VERSION ""

NS_ :

BS_:

BU_: NODE0 NODE1 NODE2 NODE3 NODE4 NODE5 NODE6 NODE7 Message4

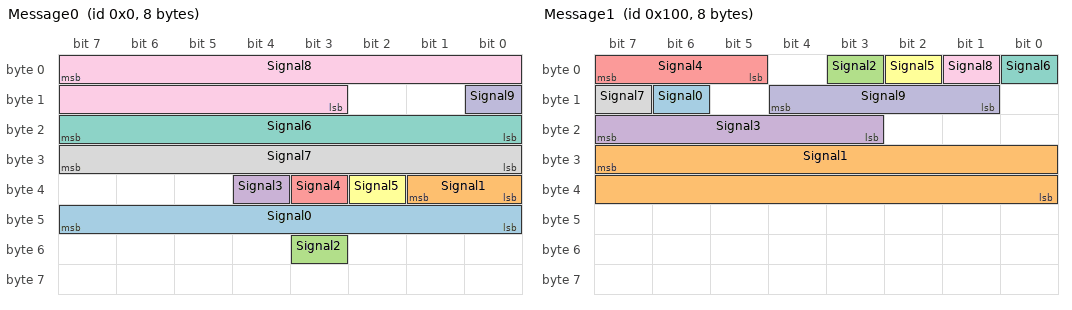
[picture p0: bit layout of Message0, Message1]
BO_ 0 Message0: 8 NODE0
 SG_ Signal0 : 47|8@0+ (1,0) [0|255] "" Vector__XXX
 SG_ Signal1 : 33|2@0+ (1,0) [0|3] "" Vector__XXX
 SG_ Signal2 : 51|1@0+ (1,0) [0|1] "" Vector__XXX
 SG_ Signal3 : 36|1@0+ (1,0) [0|1] "" Vector__XXX
 SG_ Signal4 : 35|1@0+ (1,0) [0|1] "" Vector__XXX
 SG_ Signal5 : 34|1@0+ (1,0) [0|1] "" Vector__XXX
 SG_ Signal6 : 23|8@0+ (1,-40) [-40|215] "U" Vector__XXX
 SG_ Signal7 : 31|8@0+ (0.25,0) [0|99.6] "U" Vector__XXX
 SG_ Signal8 : 7|13@0+ (0.25,0) [0|260] "U" Vector__XXX
 SG_ Signal9 : 8|1@0+ (1,0) [0|1] "" Vector__XXX

BO_ 256 Message1: 8 NODE1
 SG_ Signal0 : 14|1@0+ (1,0) [0|1] "" Vector__XXX
 SG_ Signal1 : 31|16@0+ (0.25,-16) [-16|16] "U" Vector__XXX
 SG_ Signal2 : 3|1@0+ (1,0) [0|1] "" Vector__XXX
 SG_ Signal3 : 23|5@0+ (1,0) [0|31] "" Vector__XXX
 SG_ Signal4 : 7|3@0+ (1,0) [0|7] "" Vector__XXX
 SG_ Signal5 : 2|1@0+ (1,0) [0|1] "" Vector__XXX
 SG_ Signal6 : 0|1@0+ (1,0) [0|1] "" Vector__XXX
 SG_ Signal7 : 15|1@0+ (1,0) [0|1] "" Vector__XXX
 SG_ Signal8 : 1|1@0+ (1,0) [0|1] ""  Message4
 SG_ Signal9 : 12|4@0+ (1,0) [0|15] "" Vector__XXX

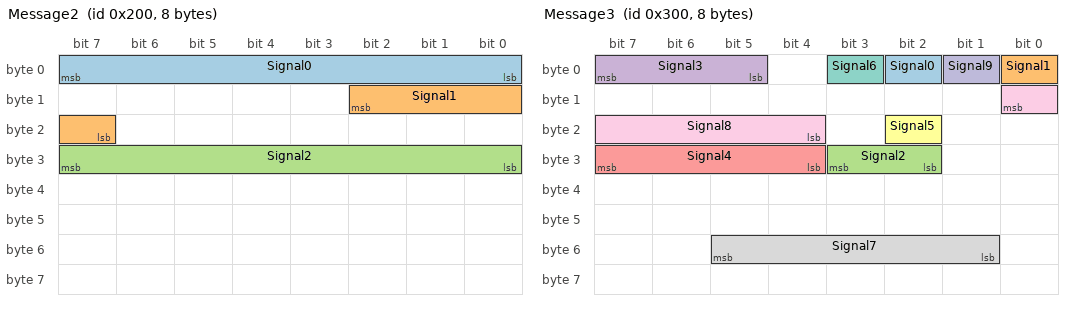
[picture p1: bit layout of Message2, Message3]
BO_ 512 Message2: 8 NODE2
 SG_ Signal0 : 7|8@0+ (1,0) [0|254] "U" Vector__XXX
 SG_ Signal1 : 10|4@0+ (1,0) [0|15] "" Vector__XXX
 SG_ Signal2 : 31|8@0+ (1,0) [0|255] "" Vector__XXX

BO_ 768 Message3: 8 NODE3
 SG_ Signal0 : 2|1@0+ (1,0) [0|1] "" Vector__XXX
 SG_ Signal1 : 0|1@0+ (1,0) [0|1] "" Vector__XXX
 SG_ Signal2 : 27|2@0+ (1,0) [0|3] "" Vector__XXX
 SG_ Signal3 : 7|3@0+ (1,0) [0|7] "" Vector__XXX
 SG_ Signal4 : 31|4@0+ (1,0) [0|15] "" Vector__XXX
 SG_ Signal5 : 18|1@0+ (1,0) [0|1] "" Vector__XXX
 SG_ Signal6 : 3|1@0+ (1,0) [0|1] "" Vector__XXX
 SG_ Signal7 : 53|5@0+ (0.1,0) [0|2.4] "U" Vector__XXX
 SG_ Signal8 : 8|5@0+ (0.1,0) [0|1.5] "bar" Vector__XXX
 SG_ Signal9 : 1|1@0+ (1,0) [0|1] "" Vector__XXX

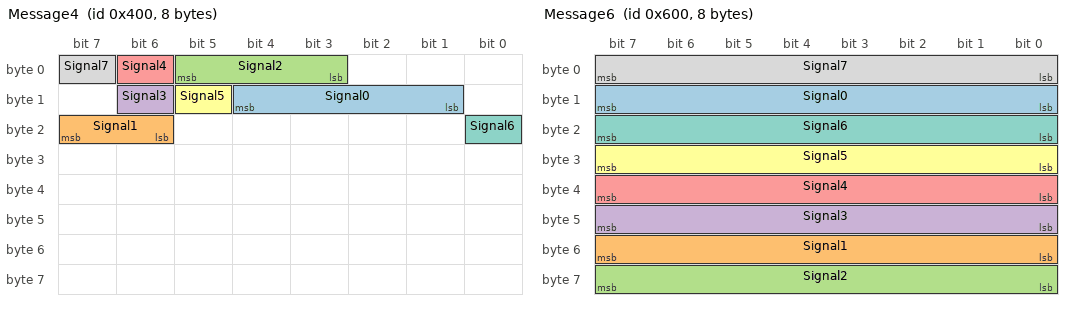
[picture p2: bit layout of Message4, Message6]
BO_ 1024 Message4: 8 NODE4
 SG_ Signal0 : 12|4@0+ (1,0) [0|15] "" Vector__XXX
 SG_ Signal1 : 23|2@0+ (1,0) [0|3] "" Vector__XXX
 SG_ Signal2 : 5|3@0+ (1,0) [0|7] "" Vector__XXX
 SG_ Signal3 : 14|1@0+ (1,0) [0|1] "" Vector__XXX
 SG_ Signal4 : 6|1@0+ (1,0) [0|1] "" Vector__XXX
 SG_ Signal5 : 13|1@0+ (1,0) [0|1] "" Vector__XXX
 SG_ Signal6 : 16|1@0+ (1,0) [0|1] "" Vector__XXX
 SG_ Signal7 : 7|1@0+ (1,0) [0|1] "" Vector__XXX

BO_ 1280 Message5: 8 NODE5
 SG_ Signal0 : 0|8@0+ (1,0) [0|256] "U" Vector__XXX
 SG_ Signal1 : 7|2@0+ (1,0) [0|3] "" Vector__XXX
 SG_ Signal2 : 3|4@0+ (1,0) [0|15] "" Vector__XXX
 SG_ Signal3 : 46|8@0+ (1,0) [0|255] "" Vector__XXX
 SG_ Signal4 : 4|1@0+ (1,0) [0|1] "" Vector__XXX
 SG_ Signal5 : 30|9@0+ (1,0) [0|260] "U" Vector__XXX

BO_ 1536 Message6: 8 NODE6
 SG_ Signal0 : 15|8@0+ (1,0) [0|255] "" Vector__XXX
 SG_ Signal1 : 55|8@0+ (1,0) [0|255] "" Vector__XXX
 SG_ Signal2 : 63|8@0+ (1,0) [0|255] "" Vector__XXX
 SG_ Signal3 : 47|8@0+ (1,0) [0|255] "" Vector__XXX
 SG_ Signal4 : 39|8@0+ (1,0) [0|255] "" Vector__XXX
 SG_ Signal5 : 31|8@0+ (1,0) [0|255] "" Vector__XXX
 SG_ Signal6 : 23|8@0+ (1,0) [0|255] "" Vector__XXX
 SG_ Signal7 : 7|8@0+ (1,0) [0|255] "" Vector__XXX

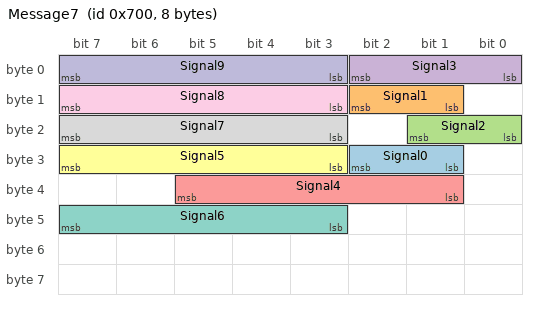
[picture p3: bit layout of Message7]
BO_ 1792 Message7: 8 NODE7
 SG_ Signal0 : 26|2@0+ (1,0) [0|3] "" Vector__XXX
 SG_ Signal1 : 10|2@0+ (1,0) [0|3] "-" Vector__XXX
 SG_ Signal2 : 17|2@0+ (1,0) [0|3] "-" Vector__XXX
 SG_ Signal3 : 2|3@0+ (1,0) [0|7] "-" Vector__XXX
 SG_ Signal4 : 37|5@0+ (1,0) [0|31] "-" Vector__XXX
 SG_ Signal5 : 31|5@0+ (1,0) [0|31] "-" Vector__XXX
 SG_ Signal6 : 47|5@0+ (1,0) [0|31] "-" Vector__XXX
 SG_ Signal7 : 23|5@0+ (1,0) [0|31] "-" Vector__XXX
 SG_ Signal8 : 15|5@0+ (1,0) [0|31] "-" Vector__XXX
 SG_ Signal9 : 7|5@0+ (1,0) [0|31] "-" Vector__XXX

BA_DEF_ SG_  "GenSigStartValue" INT 0 10000;
BA_DEF_ SG_  "GenSigSendType" ENUM  "Cyclic","OnWrite","OnWriteWithRepetition","OnChange","OnChangeWithRepetition","IfActive","IfActiveWithRepetition","NoSigSendType","NotUsed","NotUsed","NotUsed","NotUsed","NotUsed";
BA_DEF_ BO_  "GenMsgILSupport" ENUM  "No","Yes";
BA_DEF_ BO_  "GenMsgCycleTime" INT 0 50000;
BA_DEF_ BO_  "GenMsgSendType" ENUM  "Cyclic","NotUsed","NotUsed","NotUsed","NotUsed","Cyclic","NotUsed","IfActive","NoMsgSendType","NotUsed","vector_leerstring";
BA_DEF_  "BusType" STRING ;
BA_DEF_  "NmBaseAddress" HEX 1024 1087;
BA_DEF_DEF_  "GenSigStartValue" 0;
BA_DEF_DEF_  "GenSigSendType" "Cyclic";
BA_DEF_DEF_  "GenMsgILSupport" "Yes";
BA_DEF_DEF_  "GenMsgCycleTime" 0;
BA_DEF_DEF_  "GenMsgSendType" "NoMsgSendType";
BA_DEF_DEF_  "BusType" "";
BA_DEF_DEF_  "NmBaseAddress" 1024;
BA_ "BusType" "CAN";
BA_ "GenMsgSendType" BO_ 0 0;
BA_ "GenMsgCycleTime" BO_ 0 10;
BA_ "GenMsgCycleTime" BO_ 256 20;
BA_ "GenMsgSendType" BO_ 256 0;
BA_ "GenMsgCycleTime" BO_ 512 256;
BA_ "GenMsgSendType" BO_ 512 0;
BA_ "GenMsgCycleTime" BO_ 768 256;
BA_ "GenMsgSendType" BO_ 768 0;
BA_ "GenMsgCycleTime" BO_ 1024 256;
BA_ "GenMsgSendType" BO_ 1024 0;
BA_ "GenMsgCycleTime" BO_ 1280 20;
BA_ "GenMsgSendType" BO_ 1280 0;
BA_ "GenMsgSendType" BO_ 1536 7;
BA_ "GenMsgSendType" BO_ 1792 0;
BA_ "GenMsgCycleTime" BO_ 1792 50;
BA_ "GenSigStartValue" SG_ 0 Signal6 40;
VAL_ 0 Signal2 1 "State1" 0 "State0" ;
VAL_ 0 Signal3 1 "State1" 0 "State0" ;
VAL_ 0 Signal4 1 "State1" 0 "State0" ;
VAL_ 0 Signal5 1 "State1" 0 "State0" ;
VAL_ 0 Signal9 1 "State1" 0 "State0" ;
VAL_ 256 Signal0 1 "State1" 0 "State0" ;
VAL_ 256 Signal2 1 "State1" 0 "State0" ;
VAL_ 256 Signal3 6 "State6" 5 "State5" 4 "State4" 3 "State3" 2 "State2" 1 "State1" 0 "State0" ;
VAL_ 256 Signal4 7 "State7" 6 "State6" 5 "State5" 4 "State4" 3 "State3" 2 "State2" 1 "State1" 0 "State0" ;
VAL_ 256 Signal5 1 "State1" 0 "State0" ;
VAL_ 256 Signal6 1 "State1" 0 "State0" ;
VAL_ 256 Signal7 1 "State1" 0 "State0" ;
VAL_ 256 Signal8 1 "State1" 0 "State0" ;
VAL_ 768 Signal0 1 "State1" 0 "State0" ;
VAL_ 768 Signal1 1 "State1" 0 "State0" ;
VAL_ 768 Signal2 3 "State3" 2 "State2" 1 "State1" 0 "State0" ;
VAL_ 768 Signal3 7 "State7" 6 "State6" 5 "State5" 4 "State4" 3 "State3" 2 "State2" 1 "State1" 0 "State0" ;
VAL_ 768 Signal4 15 "State15" 14 "State14" 13 "State13" 12 "State12" 11 "State11" 10 "State10" 9 "State9" 8 "State8" 7 "State7" 6 "State6" 5 "State5" 4 "State4" 3 "State3" 2 "State2" 1 "State1" 0 "State0" ;
VAL_ 768 Signal5 1 "State1" 0 "State0" ;
VAL_ 768 Signal6 1 "State1" 0 "State0" ;
VAL_ 768 Signal9 1 "State1" 0 "State0" ;
VAL_ 1024 Signal0 30 "State30" 25 "State25" 24 "State24" 23 "State23" 22 "State22" 21 "State21" 20 "State20" 19 "State19" 18 "State18" 17 "State17" 16 "State16" 15 "State15" 14 "State14" 13 "State13" 12 "State12" 11 "State11" 10 "State10" 9 "State9" 8 "State8" 7 "State7" 6 "State6" 5 "State5" 4 "State4" 3 "State3" 2 "State2" 1 "State1" 0 "State0" ;
VAL_ 1024 Signal1 3 "State3" 2 "State2" 1 "State1" 0 "State0" ;
VAL_ 1024 Signal2 7 "State7" 6 "State6" 5 "State5" 4 "State4" 3 "State3" 2 "State2" 1 "State1" 0 "State0" ;
VAL_ 1024 Signal3 1 "State1" 0 "State0" ;
VAL_ 1024 Signal4 1 "State1" 0 "State0" ;
VAL_ 1024 Signal5 1 "State1" 0 "State0" ;
VAL_ 1024 Signal6 1 "State1" 0 "State0" ;
VAL_ 1024 Signal7 1 "State1" 0 "State0" ;
VAL_ 1280 Signal1 3 "State3" 2 "State2" 1 "State1" 0 "State0" ;
VAL_ 1280 Signal4 1 "State1" 0 "State0" ;
VAL_ 1792 Signal0 3 "State3" 2 "State2" 1 "State1" 0 "State0" ;
VAL_ 1792 Signal1 2 "State2" 1 "State1" 0 "State0" ;
VAL_ 1792 Signal2 2 "State2" 1 "State1" 0 "State0" ;
VAL_ 1792 Signal3 5 "State5" 4 "State4" 3 "State3" 2 "State2" 1 "State1" 0 "State0" ;
VAL_ 1792 Signal4 30 "State30" 25 "State25" 24 "State24" 23 "State23" 22 "State22" 21 "State21" 20 "State20" 19 "State19" 18 "State18" 17 "State17" 16 "State16" 15 "State15" 14 "State14" 13 "State13" 12 "State12" 11 "State11" 10 "State10" 9 "State9" 8 "State8" 7 "State7" 6 "State6" 5 "State5" 4 "State4" 3 "State3" 2 "State2" 1 "State1" 0 "State0" ;
VAL_ 1792 Signal5 30 "State30" 25 "State25" 24 "State24" 23 "State23" 22 "State22" 21 "State21" 20 "State20" 19 "State19" 18 "State18" 17 "State17" 16 "State16" 15 "State15" 14 "State14" 13 "State13" 12 "State12" 11 "State11" 10 "State10" 9 "State9" 8 "State8" 7 "State7" 6 "State6" 5 "State5" 4 "State4" 3 "State3" 2 "State2" 1 "State1" 0 "State0" ;
VAL_ 1792 Signal6 30 "State30" 25 "State25" 24 "State24" 23 "State23" 22 "State22" 21 "State21" 20 "State20" 19 "State19" 18 "State18" 17 "State17" 16 "State16" 15 "State15" 14 "State14" 13 "State13" 12 "State12" 11 "State11" 10 "State10" 9 "State9" 8 "State8" 7 "State7" 6 "State6" 5 "State5" 4 "State4" 3 "State3" 2 "State2" 1 "State1" 0 "State0" ;
VAL_ 1792 Signal7 30 "State30" 25 "State25" 24 "State24" 23 "State23" 22 "State22" 21 "State21" 20 "State20" 19 "State19" 18 "State18" 17 "State17" 16 "State16" 15 "State15" 14 "State14" 13 "State13" 12 "State12" 11 "State11" 10 "State10" 9 "State9" 8 "State8" 7 "State7" 6 "State6" 5 "State5" 4 "State4" 3 "State3" 2 "State2" 1 "State1" 0 "State0" ;
VAL_ 1792 Signal8 30 "State30" 25 "State25" 24 "State24" 23 "State23" 22 "State22" 21 "State21" 20 "State20" 19 "State19" 18 "State18" 17 "State17" 16 "State16" 15 "State15" 14 "State14" 13 "State13" 12 "State12" 11 "State11" 10 "State10" 9 "State9" 8 "State8" 7 "State7" 6 "State6" 5 "State5" 4 "State4" 3 "State3" 2 "State2" 1 "State1" 0 "State0" ;
VAL_ 1792 Signal9 30 "State30" 25 "State25" 24 "State24" 23 "State23" 22 "State22" 21 "State21" 20 "State20" 19 "State19" 18 "State18" 17 "State17" 16 "State16" 15 "State15" 14 "State14" 13 "State13" 12 "State12" 11 "State11" 10 "State10" 9 "State9" 8 "State8" 7 "State7" 6 "State6" 5 "State5" 4 "State4" 3 "State3" 2 "State2" 1 "State1" 0 "State0" ;
